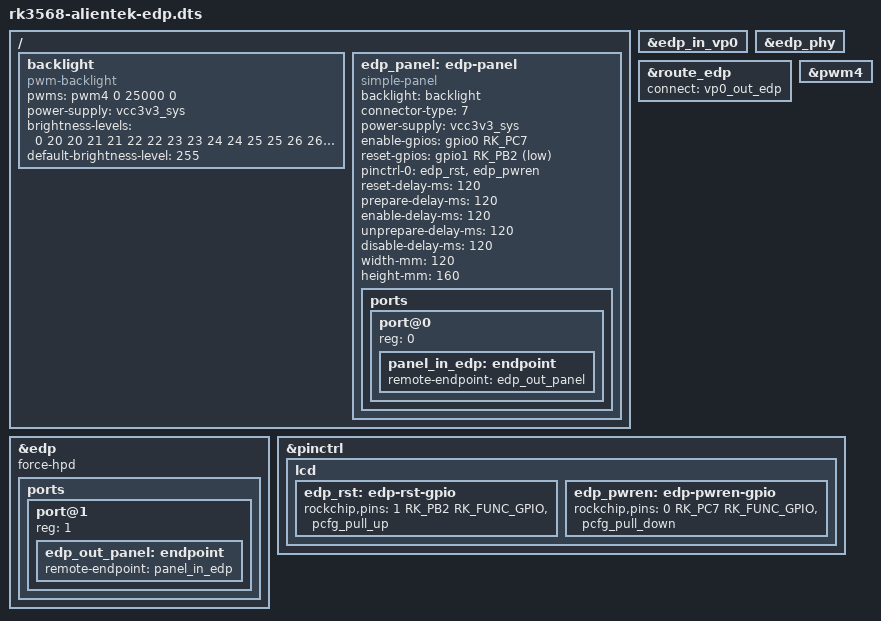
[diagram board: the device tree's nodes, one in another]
// SPDX-License-Identifier: (GPL-2.0+ OR MIT)
/*
 * Copyright (c) 2021 Rockchip Electronics Co., Ltd.
 */

/dts-v1/;
#include "rk3568-alientek.dtsi"

/{
	backlight: backlight {
		status = "okay";
		compatible = "pwm-backlight";
		pwms = <&pwm4 0 25000 0>;
		power-supply = <&vcc3v3_sys>;
		brightness-levels = <
			  0  20  20  21  21  22  22  23
			 23  24  24  25  25  26  26  27
			 27  28  28  29  29  30  30  31
			 31  32  32  33  33  34  34  35
			 35  36  36  37  37  38  38  39
			 40  41  42  43  44  45  46  47
			 48  49  50  51  52  53  54  55
			 56  57  58  59  60  61  62  63
			 64  65  66  67  68  69  70  71
			 72  73  74  75  76  77  78  79
			 80  81  82  83  84  85  86  87
			 88  89  90  91  92  93  94  95
			 96  97  98  99 100 101 102 103
			104 105 106 107 108 109 110 111
			112 113 114 115 116 117 118 119
			120 121 122 123 124 125 126 127
			128 129 130 131 132 133 134 135
			136 137 138 139 140 141 142 143
			144 145 146 147 148 149 150 151
			152 153 154 155 156 157 158 159
			160 161 162 163 164 165 166 167
			168 169 170 171 172 173 174 175
			176 177 178 179 180 181 182 183
			184 185 186 187 188 189 190 191
			192 193 194 195 196 197 198 199
			200 201 202 203 204 205 206 207
			208 209 210 211 212 213 214 215
			216 217 218 219 220 221 222 223
			224 225 226 227 228 229 230 231
			232 233 234 235 236 237 238 239
			240 241 242 243 244 245 246 247
			248 249 250 251 252 253 254 255
		>;
		default-brightness-level = <255>;
	};

	edp_panel: edp-panel {
		compatible = "simple-panel";
		backlight = <&backlight>;
		connector-type = <7>;
		power-supply = <&vcc3v3_sys>;
		enable-gpios = <&gpio0 RK_PC7 GPIO_ACTIVE_HIGH>;
		reset-gpios = <&gpio1 RK_PB2 GPIO_ACTIVE_LOW>;
		//bus-format = <MEDIA_BUS_FMT_RBG888_1X24>;
		pinctrl-names = "default";
		pinctrl-0 = <&edp_rst &edp_pwren>;

/*		reset-delay-ms = <60>;
		prepare-delay-ms = <60>;
		enable-delay-ms = <60>;
		unprepare-delay-ms = <60>;
		disable-delay-ms = <60>;*/

		reset-delay-ms = <120>;
		prepare-delay-ms = <120>;
		enable-delay-ms = <120>;
		unprepare-delay-ms = <120>;
		disable-delay-ms = <120>;
		width-mm = <120>;
		height-mm = <160>;

		ports {
			#address-cells = <1>;
			#size-cells = <0>;

			port@0 {
				reg = <0>;
				panel_in_edp: endpoint {
					remote-endpoint = <&edp_out_panel>;
				};
			};
		};
	};
};

&edp {
	/delete-property/ hpd-gpios;
	force-hpd;
	//hpd-gpios = <&gpio0 RK_PC2 GPIO_ACTIVE_HIGH>; //使用eDP屏需将hpd-gpios注释掉!
	status = "okay";

	//pinctrl-names = "default";
	//pinctrl-0 = <&edpdpm1_pins>;

	ports {
		port@1 {
			reg = <1>;
			edp_out_panel: endpoint {
				remote-endpoint = <&panel_in_edp>;
			};
		};
	};
};

&edp_in_vp0 {
	status = "okay";
};

&edp_phy {
	status = "okay";
};

&edp_panel {
	status = "okay";
};

&route_edp {
	connect = <&vp0_out_edp>;
	status = "okay";
};

&pwm4 {
	status = "okay";
};

&pinctrl {
	lcd {
		edp_rst: edp-rst-gpio {
			rockchip,pins = <1 RK_PB2 RK_FUNC_GPIO &pcfg_pull_up>;
		};

		edp_pwren: edp-pwren-gpio {
			rockchip,pins = <0 RK_PC7 RK_FUNC_GPIO &pcfg_pull_down>;
		};
	};
};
